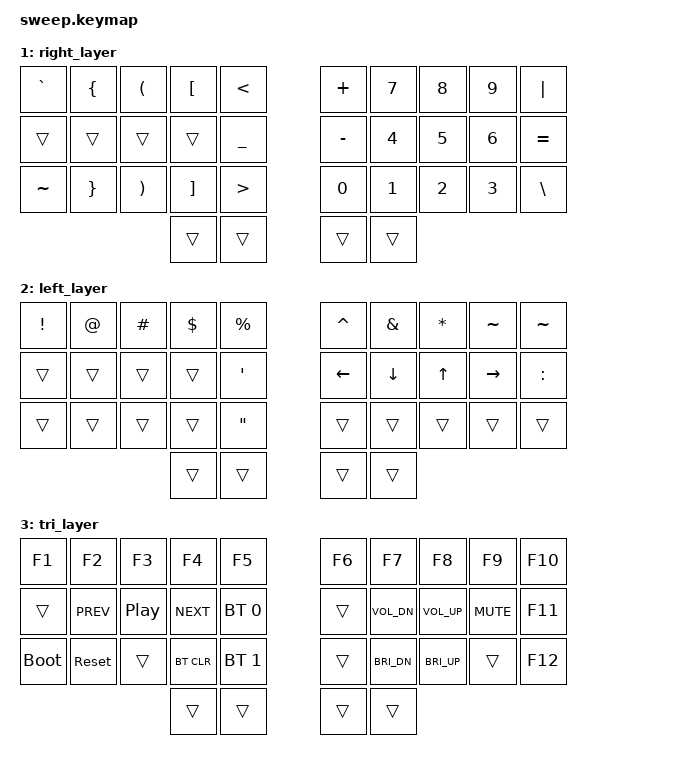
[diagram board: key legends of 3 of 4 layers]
// Copyright (c) 2022 The ZMK Contributors
// SPDX-License-Identifier: MIT

#include <behaviors.dtsi>
#include <dt-bindings/zmk/keys.h>
#include <dt-bindings/zmk/bt.h>

// Home row mods macro
#define HRML(k1,k2,k3,k4) &mt LCTRL k1  &mt LALT k2  &mt LGUI k3  &mt LSHFT k4
#define HRMR(k1,k2,k3,k4) &mt RSHFT k1  &mt RGUI k2  &mt RALT k3  &mt RCTRL k4

/ {
    behaviors {
        ht: hold_tap {
            compatible = "zmk,behavior-hold-tap";
            #binding-cells = <2>;
            flavor = "tap-preferred";
            tapping-term-ms = <220>;
            quick-tap-ms = <150>;
            require-prior-idle-ms = <100>;
            bindings = <&kp>, <&kp>;
        };
        td_l1: tap_dance_layer_1 {
            compatible = "zmk,behavior-tap-dance";
            #binding-cells = <0>;
            tapping-term-ms = <200>;
            bindings = <&lt 1 SQT>, <&kp tog 1>;
        };
        td_l2: tap_dance_layer_2 {
            compatible = "zmk,behavior-tap-dance";
            #binding-cells = <0>;
            tapping-term-ms = <200>;
            bindings = <&lt 2 TAB>, <&kp tog 2>;
        };
    };

    combos {
        compatible = "zmk,combos";
        combo_enter {
            timeout-ms = <50>;
            key-positions = <31 32>;
            bindings = <&kp RET>;
        };
        combo_escl {
            timeout-ms = <50>;
            key-positions = <12 13>;
            bindings = <&kp ESC>;
        };
        combo_escr {
            timeout-ms = <50>;
            key-positions = <16 17>;
            bindings = <&kp ESC>;
        };
        combo_caps {
            timeout-ms = <50>;
            key-positions = <6 7>;
            bindings = <&kp CAPS>;
        };
        combo_tab {
            timeout-ms = <50>;
            key-positions = <2 3>;
            bindings = <&kp TAB>;
        };
    };

    conditional_layers {
        compatible = "zmk,conditional-layers";
        tri_layer {
            if-layers = <1 2>;
            then-layer = <3>;
        };
    };

    keymap {
        compatible = "zmk,keymap";
        default_layer {
            bindings = <
        //╭──────────┬──────────┬──────────┬──────────┬──────────╮   ╭──────────┬──────────┬──────────┬──────────┬──────────╮
        //│  Q       │  W       │  E       │  R       │  T       │   │  Y       │  U       │  I       │  O       │  P       │
            &kp Q      &kp W      &kp E      &kp R      &kp T          &kp Y      &kp U      &kp I      &kp O      &kp P
        //├──────────┼──────────┼──────────┼──────────┼──────────┤   ├──────────┼──────────┼──────────┼──────────┼──────────┤
        //│  A       │  S       │  D       │  F       │  G       │   │  H       │  J       │  K       │  L       │ ; :      │
            HRML(A,        S,         D,         F)     &kp G          &kp H      HRMR(J,        K,         L,       SEMI)
        //├──────────┼──────────┼──────────┼──────────┼──────────┤   ├──────────┼──────────┼──────────┼──────────┼──────────┤
        //│  Z       │  X       │  C       │  V       │  B       │   │  N       │  M       │ , <      │ . >      │ / ?      │
            &kp Z      &mt LG(X) X &mt LG(C) C &mt LG(V) V &kp B       &kp N      &kp M      &kp COMMA  &kp DOT    &kp FSLH
        //╰──────────┴──────────┴──────────┼──────────┼──────────┤   ├──────────┼──────────┼──────────┴──────────┴──────────╯
                                             &td_l2     &kp BSPC       &kp SPACE  &td_l1
        //                                 ╰──────────┴──────────╯   ╰──────────┴──────────╯
            >;
        };

        right_layer {
            bindings = <
        //╭──────────┬──────────┬──────────┬──────────┬──────────╮   ╭──────────┬──────────┬──────────┬──────────┬──────────╮
        //│  ` ~     │  {       │  (       │  [       │  <       │   │  +       │  7 &     │  8 *     │  9 (     │  |       │
            &kp GRAVE  &kp LBRC   &kp LPAR   &kp LBKT   &kp LT         &kp PLUS   &kp N7     &kp N8     &kp N9     &kp PIPE
        //├──────────┼──────────┼──────────┼──────────┼──────────┤   ├──────────┼──────────┼──────────┼──────────┼──────────┤
        //│          │          │          │          │  _       │   │  - _     │  4 $     │  5 %     │  6 ^     │  = +     │
            &trans     &trans     &trans     &trans     &kp UNDER      &kp MINUS  &kp N4     &kp N5     &kp N6     &kp EQUAL
        //├──────────┼──────────┼──────────┼──────────┼──────────┤   ├──────────┼──────────┼──────────┼──────────┼──────────┤
        //│  ~       │  }       │  )       │  ]       │  >       │   │  0 )     │  1 !     │  2 @     │  3 #     │  \ |     │
            &kp TILDE  &kp RBRC   &kp RPAR   &kp RBKT   &kp GT         &kp N0     &kp N1     &kp N2     &kp N3     &kp BSLH
        //╰──────────┴──────────┴──────────┼──────────┼──────────┤   ├──────────┼──────────┼──────────┴──────────┴──────────╯
                                             &trans     &trans         &trans     &trans
        //                                 ╰──────────┴──────────╯   ╰──────────┴──────────╯
            >;
        };

        left_layer {
            bindings = <
        //╭──────────┬──────────┬──────────┬──────────┬──────────╮   ╭──────────┬──────────┬──────────┬──────────┬──────────╮
        //│  !       │  @       │  #       │  $       │  %       │   │  ^       │  &       │  *       │  ~       │  ~       │
            &kp EXCL   &kp AT     &kp HASH   &kp DLLR   &kp PRCNT      &kp CARET  &kp AMPS   &kp ASTRK  &kp TILDE  &kp TILDE
        //├──────────┼──────────┼──────────┼──────────┼──────────┤   ├──────────┼──────────┼──────────┼──────────┼──────────┤
        //│          │          │          │          │  ' "     │   │          │          │          │          │  :       │
            &trans     &trans     &trans     &trans     &kp SQT        &kp LEFT   &kp DOWN   &kp UP     &kp RIGHT  &kp COLON
        //├──────────┼──────────┼──────────┼──────────┼──────────┤   ├──────────┼──────────┼──────────┼──────────┼──────────┤
        //│          │          │          │          │  "       │   │          │          │          │          │          │
            &trans     &trans     &trans     &trans     &kp DQT        &trans     &trans     &trans     &trans     &trans
        //╰──────────┴──────────┴──────────┼──────────┼──────────┤   ├──────────┼──────────┼──────────┴──────────┴──────────╯
                                             &trans     &trans         &trans     &trans
        //                                 ╰──────────┴──────────╯   ╰──────────┴──────────╯
            >;
        };

        tri_layer {
            bindings = <
        //╭──────────┬──────────┬──────────┬──────────┬──────────╮   ╭──────────┬──────────┬──────────┬──────────┬──────────╮
        //│          │          │          │          │          │   │          │          │          │          │          │
            &kp F1     &kp F2     &kp F3     &kp F4     &kp F5         &kp F6     &kp F7     &kp F8     &kp F9     &kp F10
        //├──────────┼──────────┼──────────┼──────────┼──────────┤   ├──────────┼──────────┼──────────┼──────────┼──────────┤
        //│          │          │          │          │PROFILE 0 │   │          │          │          │          │          │
           &trans      &kp C_PREV &kp C_PP   &kp C_NEXT &bt BT_SEL 0    &trans   &kp C_VOL_DN &kp C_VOL_UP &kp K_MUTE &kp F11
        //├──────────┼──────────┼──────────┼──────────┼──────────┤   ├──────────┼──────────┼──────────┼──────────┼──────────┤
        //│BOOTLOADER│ RESET    │          │ CLEAR BT │PROFILE 1 │   │          │          │          │          │          │
          &bootloader &sys_reset  &trans    &bt BT_CLR &bt BT_SEL 1    &trans   &kp C_BRI_DN &kp C_BRI_UP &trans   &kp F12
        //╰──────────┴──────────┴──────────┼──────────┼──────────┤   ├──────────┼──────────┼──────────┴──────────┴──────────╯
                                             &trans     &trans         &trans     &trans
        //                                 ╰──────────┴──────────╯   ╰──────────┴──────────╯
            >;
        };
    };
};
